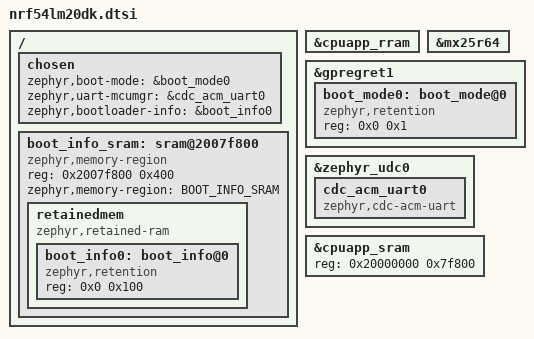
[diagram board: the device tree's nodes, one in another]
/* nRF54LM20 DK mcuboot layout.
 *
 * The upstream board DTS defines a zephyr,mapped-partition layout on
 * cpuapp_rram (vendor/nordic/nrf54lm20a_cpuapp_partition.dtsi) for direct XIP
 * boot. This overlay deletes it and replaces it with a fixed-partitions mcuboot
 * layout so the board boots via mcuboot (Adaboot) instead: the bootloader lives
 * in boot_partition and the application in slot0_partition on internal RRAM, with
 * the slot1 update image and the filesystem on the external MX25R6435F QSPI
 * NOR. The board's own zephyr,code-partition = &slot0_partition (set in
 * nrf54lm20dk_nrf54lm20a_cpuapp.dts) resolves to the fixed-partition slot0
 * defined here; the bootloader image overrides it to &boot_partition via
 * boot/zephyr/app.overlay.
 *
 * The partition geometry lives in nrf54lm20dk-partitions.dtsi (generated by
 * `python3 tools/partition_layout.py --fix nrf54lm20dk`), which this file
 * includes at the bottom; the glue in this file (delete-node, external flash
 * enablement, boot-mode retention, chosen) is hand-maintained so the overlay
 * is self-contained for both the bootloader and application images.
 */

/* Delete Zephyr-default (mapped) partitions before redefining as fixed. */
&cpuapp_rram { /delete-node/ partitions; };

&mx25r64 {
	status = "okay";
};

&gpregret1 {
	status = "okay";

	boot_mode0: boot_mode@0 {
		compatible = "zephyr,retention";
		status = "okay";
		reg = <0x0 0x1>;
	};
};

/* CDC ACM serial recovery port on the native USB device controller
 * (zephyr_udc0 = &usbhs, enabled in the upstream board DTS). The
 * bootloader's combined update mode exposes this serial port and the UF2
 * mass storage drive simultaneously on one USB device. */
&zephyr_udc0 {
	cdc_acm_uart0: cdc_acm_uart0 {
		compatible = "zephyr,cdc-acm-uart";
	};
};

/ {
	chosen {
		zephyr,boot-mode = &boot_mode0;
		/* Route serial recovery (SMP/mcumgr) to the CDC ACM port on the
		 * native USB controller instead of the uart20 console, so the
		 * VCOM UART stays the log console and the bootloader's combined
		 * update mode serves mcumgr over USB (alongside the UF2 drive). */
		zephyr,uart-mcumgr = &cdc_acm_uart0;
	};
};

#include "nrf54lm20dk-partitions.dtsi"

/* Bootloader info shared-data area: the last KB of this board's RAM, kept
 * out of the managed RAM so neither image clobbers it. The bootloader
 * writes its boot state here on every boot (BOOT_SHARE_DATA_BOOTINFO ->
 * BLINFO TLVs via boot_write_shared_data()); the application reads the
 * same region to answer the SMP bootloader-info command (RETENTION_
 * BOOTLOADER_INFO_TYPE_MCUBOOT). Carved here because this dtsi applies to
 * both images. */
&cpuapp_sram {
	reg = <0x20000000 0x7f800>;
};

/ {
	chosen {
		zephyr,bootloader-info = &boot_info0;
	};

	boot_info_sram: sram@2007f800 {
		compatible = "zephyr,memory-region", "mmio-sram";
		reg = <0x2007f800 0x400>;
		zephyr,memory-region = "BOOT_INFO_SRAM";
		status = "okay";

		retainedmem {
			compatible = "zephyr,retained-ram";
			status = "okay";
			#address-cells = <1>;
			#size-cells = <1>;

			boot_info0: boot_info@0 {
				compatible = "zephyr,retention";
				status = "okay";
				reg = <0x0 0x100>;
			};
		};
	};
};
